# NUC200AN_v1 register map
File version: 1.0
Registers are 32-bit, read-write, reset 0x0 unless marked. A register's access mark holds for its fields unless they carry their own. Offsets are from the block's base; [hi:lo] are bit positions; {n}, {i} and the like mark numbered series; 'fields as' and 'values as' point back to an identical list.

## CLK — CLK Register Map
Base 0x50000200
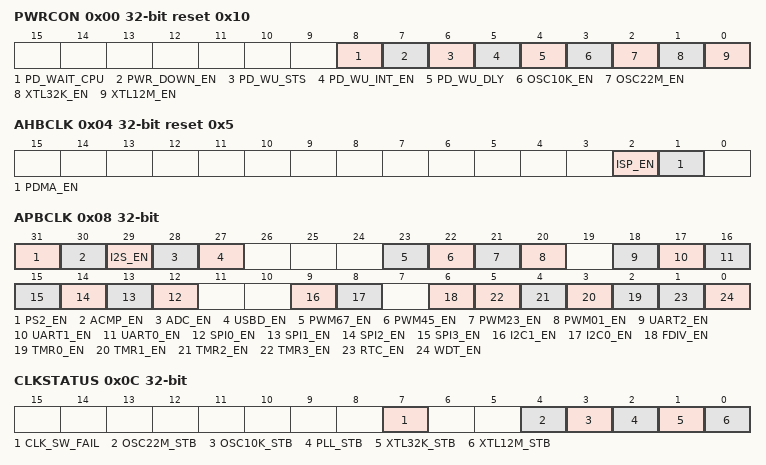
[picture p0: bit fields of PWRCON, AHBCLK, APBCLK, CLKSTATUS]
0x00 PWRCON reset 0x10 (reset mask 0xFFFFFFF0) — System Power-down Control Register
  [8] PD_WAIT_CPU — This Bit Control the Power-down Entry Condition (Write Protected)
    0=Chip enters Power-down mode when the PWR_DOWN_EN bit is set to 1; 1=Chip enters Power- down mode when the both PD_WAIT_CPU and PWR_DOWN_EN bits are set to 1 and CPU run WFI instruction
  [7] PWR_DOWN_EN — System Power-down Enable Bit (Write Protected). When this bit is set to 1, Power-down mode is enabled and chip power-down behavior will depend on the PD_WAIT_CPU bit (a) If the PD_WAIT_CPU is 0, then the chip enters Power-down mode immediately after the PWR_DOWN_EN bit set. (b) if the PD_WAIT_CPU is 1, then the chip keeps active till the CPU sleep mode is also active and then the chip enters Power-down mode. When chip wakes up from Power-down mode, this bit is cleared by hardware. User needs to set this bit again for next power-down. In Power-down mode, external 4~24 MHz high speed crystal oscillator and the internal 22.1184 MHz high speed oscillator will be disabled in this mode, but the external 32.768 kHz low speed crystal and internal 10 kHz low speed oscillator are not controlled by Power-down mode. In Power- down mode, the PLL and system clock are disabled, and ignored the clock source selection. The clocks of peripheral are not controlled by Power-down mode, if the peripheral clock source is from external 32.768 kHz low speed crystal oscillator or the internal 10 kHz low speed oscillator.
    0=Chip operating normally or chip in Idle mode because of WFI command; 1=Chip enters Power-down mode instantly or waits CPU sleep command WFI
  [6] PD_WU_STS — Power-down Mode Wake-up Interrupt Status. Set by "power-down wake-up event", it indicates that resume from Power-down mode" The flag is set if the GPIO, USB, UART, WDT, CAN, I2C, TIMER, ACMP, BOD or RTC wake-up occurred. Write 1 to clear the bit to 0. Note: This bit is working only if PD_WU_INT_EN (PWRCON[5]) set to 1.
  [5] PD_WU_INT_EN — Power-down Mode Wake-up Interrupt Enable (Write Protected). The interrupt will occur when both PD_WU_STS and PD_WU_INT_EN are high.
    0=Interrupt Disabled; 1=Interrupt Enabled
  [4] PD_WU_DLY — Enable the Wake-up Delay Counter (Write Protected). When the chip wakes up from Power-down mode, the clock control will delay certain clock cycles to wait system clock stable. The delayed clock cycle is 4096 clock cycles when chip work at external 4~24 MHz high speed crystal, and 256 clock cycles when chip work at internal 22.1184 MHz high speed oscillator.
    0=Clock cycles delay Disabled; 1=Clock cycles delay Enabled
  [3] OSC10K_EN — Internal 10 KHz Low Speed Oscillator Enable (Write Protected)
    0=Internal 10 kHz low speed oscillator Disabled; 1=Internal 10 kHz low speed oscillator Enabled
  [2] OSC22M_EN — Internal 22.1184 MHz High Speed Oscillator Enable (Write Protected)
    0=Internal 22.1184 MHz high speed oscillator Disabled; 1=Internal 22.1184 MHz high speed oscillator Enabled
  [1] XTL32K_EN — External 32.768 KHz Low Speed Crystal Enable (Write Protected)
    0=External 32.768 kHz low speed crystal oscillator Disabled; 1=External 32.768 kHz low speed crystal oscillator Enabled (Normal operation)
  [0] XTL12M_EN — External 4~24 MHz High Speed Crystal Enable (Write Protected). The bit default value is set by flash controller user configuration register config0 [26:24]. When the default clock source is from external 4~24 MHz high speed crystal, this bit is set to 1 automatically.
    0=External 4~24 MHz high speed crystal oscillator Disabled; 1=External 4~24 MHz high speed crystal oscillator Enabled
0x04 AHBCLK reset 0x5 — AHB Devices Clock Enable Control Register
  [2] ISP_EN — Flash ISP Controller Clock Enable Control
    0=Flash ISP peripheral clock Disabled; 1=Flash ISP peripheral clock Enabled
  [1] PDMA_EN — PDMA Controller Clock Enable Control
    0=PDMA peripheral clock Disabled; 1=PDMA peripheral clock Enabled
0x08 APBCLK (reset mask 0xFFFFFFF0) — APB Devices Clock Enable Control Register
  [31] PS2_EN — PS/2 Clock Enable
    0=PS/2 clock Disabled; 1=PS/2 clock Enabled
  [30] ACMP_EN — Analog Comparator Clock Enable
    0=Analog Comparator clock Disabled; 1=Analog Comparator clock Enabled
  [29] I2S_EN — I2S Clock Enable
    0=I2S clock Disabled; 1=I2S clock Enabled
  [28] ADC_EN — Analog-digital-converter (ADC) Clock Enable
    0=ADC clock Disabled; 1=ADC clock Enabled
  [27] USBD_EN — USB 2.0 FS Device Controller Clock Enable
    0=USB clock Enabled; 1=USB clock Enabled
  [23] PWM67_EN — PWM_67 Clock Enable
    0=PWM67 clock Disabled; 1=PWM67 clock Enabled
  [22] PWM45_EN — PWM_45 Clock Enable
    0=PWM45 clock Disabled; 1=PWM45 clock Enabled
  [21] PWM23_EN — PWM_23 Clock Enable
    0=PWM23 clock Disabled; 1=PWM23 clock Enabled
  [20] PWM01_EN — PWM_01 Clock Enable
    0=PWM01 clock Disabled; 1=PWM01 clock Enabled
  [18] UART2_EN — UART2 Clock Enable
    0=UART2 clock Disabled; 1=UART2 clock Enabled
  [17] UART1_EN — UART1 Clock Enable
    0=UART1 clock Disabled; 1=UART1 clock Enabled
  [16] UART0_EN — UART0 Clock Enable
    0=UART0 clock Disabled; 1=UART0 clock Enabled
  [n+12] SPI{n}_EN (n=0..3) — SPI{n} Clock Enable
    0=SPI{n} clock Disabled; 1=SPI{n} clock Enabled
  [9] I2C1_EN — I2C1 Clock Enable
    0=I2C1 clock Disabled; 1=I2C1 clock Enabled
  [8] I2C0_EN — I2C0 Clock Enable
    0=I2C0 clock Disabled; 1=I2C0 clock Enabled
  [6] FDIV_EN — Frequency Divider Output Clock Enable
    0=FDIV clock Disabled; 1=FDIV clock Enabled
  [n+2] TMR{n}_EN (n=0..3) — Timer{n} Clock Enable
    0=Timer{n} clock Disabled; 1=Timer{n} clock Enabled
  [1] RTC_EN — Real-time-clock APB Interface Clock Enable. This bit is used to control the RTC APB clock only, The RTC peripheral clock source is from the external 32.768 kHz low speed crystal.
    0=RTC clock Disabled; 1=RTC clock Enabled
  [0] WDT_EN — Watchdog Timer Clock Enable (Write Protected). This bit is the protected bit. It means programming this needs to write "59h", "16h", "88h" to address 0x5000_0100 to disable register protection. Refer to the register REGWRPROT at address GCR_BA+0x100.
    0=Watchdog Timer clock Disabled; 1=Watchdog Timer clock Enabled
0x0C CLKSTATUS (reset mask 0xFFFFFF00) — Clock Status Monitor Register
  [7] CLK_SW_FAIL — Clock Switching Fail Flag. This bit is updated when software switches system clock source. If switch target clock is stable, this bit will be set to 0. If switch target clock is not stable, this bit will be set to 1. Write 1 to clear the bit to 0.
    0=Clock switching success; 1=Clock switching failed
  [4] OSC22M_STB — Internal 22.1184 MHz High Speed Oscillator Clock Source Stable Flag. This bit is read only.
    0=Internal 22.1184 MHz high speed oscillator clock is not stable or disabled; 1=Internal 22.1184 MHz high speed oscillator clock is stable
  [3] OSC10K_STB — Internal 10 KHz Low Speed Oscillator Clock Source Stable Flag. This bit is read only.
    0=Internal 10 kHz low speed oscillator clock is not stable or disabled; 1=Internal 10 kHz low speed oscillator clock is stable
  [2] PLL_STB — Internal PLL Clock Source Stable Flag. This bit is read only.
    0=Internal PLL clock is not stable or disabled; 1=Internal PLL clock is stable
  [1] XTL32K_STB — External 32.768 KHz Low Speed Crystal Clock Source Stable Flag. This bit is read only.
    0=External 32.768 kHz low speed crystal clock is not stable or disabled; 1=External 32.768 kHz low speed crystal clock is stable
  [0] XTL12M_STB — External 4~24 MHz High Speed Crystal Clock Source Stable Flag. This bit is read only.
    0=External 4~24 MHz high speed crystal clock is not stable or disabled; 1=External 4~24 MHz high speed crystal clock is stable
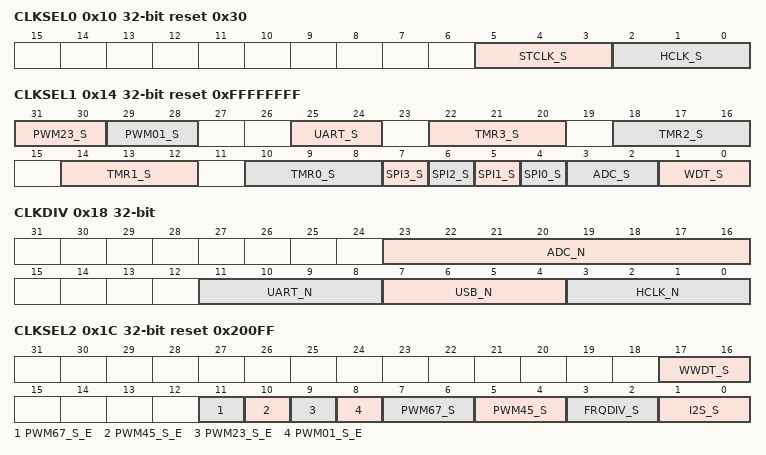
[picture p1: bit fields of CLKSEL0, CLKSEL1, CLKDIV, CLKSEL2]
0x10 CLKSEL0 reset 0x30 (reset mask 0xFFFFFFF0) — Clock Source Select Control Register 0
  [5:3] STCLK_S — Cortex-M0 SysTick Clock Source Select (Write-protection Bits)
    0=Clock source from external 4~24 MHz high speed crystal clock; 1=Clock source from external 32.768 kHz low speed crystal clock; 2=Clock source from external 4~24 MHz high speed crystal clock/2; 3=Clock source from HCLK/2; 7=Clock source from internal 22.1184 MHz high speed oscillator clock/2
  [2:0] HCLK_S — HCLK Clock Source Select (Write-protection Bits). Before clock switching, the related clock sources (both pre-select and new-select) must be turn on. The 3-bit default value is reloaded from the value of CFOSC (Config0[26:24]) in user configuration register of Flash controller by any reset. Therefore the default value is either 000b or 111b. These bits are protected bit. It means programming them needs to write "59h", "16h", and "88h" to address 0x5000_0100 to disable register protection. Refer to the register REGWRPROT at address GCR_BA+0x100.
    0=Clock source from external 4~24 MHz high speed crystal oscillator clock; 1=Clock source from external 32.768 kHz low speed crystal oscillator clock; 2=Clock source from PLL clock; 3=Clock source from internal 10 kHz low speed oscillator clock; 7=Clock source from internal 22.1184 MHz high speed oscillator clock
0x14 CLKSEL1 reset 0xFFFFFFFF — Clock Source Select Control Register 1
  [31:30] PWM23_S — PWM2 and PWM3 Clock Source Selection. PWM2 and PWM3 use the same Peripheral clock source; both of them use the same prescaler. The Peripheral clock source of PWM2 and PWM3 is defined by PWM23_S[2:0] and this field is combined by CLKSEL2[9] and CLKSEL1[31:30].
  [29:28] PWM01_S — PWM0 and PWM1 Clock Source Selection. PWM0 and PWM1 use the same Peripheral clock source, both of them use the same prescaler. The Peripheral clock source of PWM0 and PWM1 is defined by PWM01_S[2:0] and this field is combined by CLKSEL2[8] and CLKSEL1[29:28].
  [25:24] UART_S — UART Clock Source Selection
    0=Clock source from external 4~24 MHz high speed crystal oscillator clock; 1=Clock source from PLL clock; 3=Clock source from internal 22.1184 MHz high speed oscillator clock
  [4n+10:4n+8] TMR{n}_S (n=0..3) — TIMER{n} Clock Source Selection
    0=Clock source from external 4~24 MHz high speed crystal clock; 1=Clock source from external 32.768 kHz low speed crystal clock; 2=Clock source from HCLK; 3=Clock source from external trigger; 5=Clock source from internal 10 kHz low speed oscillator clock; 7=Clock source from internal 22.1184 MHz high speed oscillator clock
  [n+4] SPI{n}_S (n=0..3) — SPI{n} Clock Source Selection
    0=Clock source from PLL clock; 1=Clock source from HCLK
  [3:2] ADC_S — ADC Clock Source Select
    0=Clock source from external 4~24 MHz high speed crystal oscillator clock; 1=Clock source from PLL clock; 2=Clock source from HCLK; 3=Clock source from internal 22.1184 MHz high speed oscillator clock
  [1:0] WDT_S — Watchdog Timer Clock Source Select (Write-protection Bits). These bits are protected bits, and programming this needs to write "59h", "16h", and "88h" to address 0x5000_0100 to disable register protection. Refer to the register REGWRPROT at address GCR_BA+0x100.
    1=Clock source from external 32.768 kHz low speed crystal oscillator clock; 2=Clock source from HCLK/2048 clock; 3=Clock source from internal 10 kHz low speed oscillator clock
0x18 CLKDIV — Clock Divider Number Register
  [23:16] ADC_N — ADC Clock Divide Number From ADC Clock Source
  [11:8] UART_N — UART Clock Divide Number From UART Clock Source
  [7:4] USB_N — USB Clock Divide Number From PLL Clock
  [3:0] HCLK_N — HCLK Clock Divide Number From HCLK Clock Source
0x1C CLKSEL2 reset 0x200FF — Clock Source Select Control Register 2
  [17:16] WWDT_S — Window Watchdog Timer Clock Source Selection
    2=Clock source from HCLK/2048 clock; 3=Clock source from internal 10 kHz low speed oscillator clock
  [11] PWM67_S_E — PWM6 and PWM7 Clock Source Selection. PWM6 and PWM7 used the same Peripheral clock source; both of them used the same prescaler. The Peripheral clock source of PWM6 and PWM7 is defined by PWM67_S[2:0] and this field is combined by CLKSEL2[11] and CLKSEL2[7:6].
  [10] PWM45_S_E — PWM4 and PWM5 Clock Source Selection. PWM4 and PWM5 used the same Peripheral clock source; both of them used the same prescaler. The Peripheral clock source of PWM4 and PWM5 is defined by PWM45_S[2:0] and this field is combined by CLKSEL2[10] and CLKSEL2[5:4].
  [9] PWM23_S_E — PWM2 and PWM3 Clock Source Selection. PWM2 and PWM3 used the same Peripheral clock source; both of them used the same prescaler. The Peripheral clock source of PWM2 and PWM3 is defined by PWM23_S[2:0] and this field is combined by CLKSEL2[9] and CLKSEL1[31:30].
  [8] PWM01_S_E — PWM0 and PWM1 Clock Source Selection. PWM0 and PWM1 used the same Peripheral clock source; both of them used the same prescaler. The Peripheral clock source of PWM0 and PWM1 is defined by PWM01_S[2:0] and this field is combined by CLKSEL2[8] and CLKSEL1[29:28].
  [7:6] PWM67_S — PWM6 and PWM7 Clock Source Selection. PWM6 and PWM7 used the same Peripheral clock source; both of them used the same prescaler. The Peripheral clock source of PWM6 and PWM7 is defined by PWM67_S (CLKSEL2[7:6]) and PWM67_S_E (CLKSEL2[11]). this field is combined by CLKSEL2[11] and CLKSEL2[7:6].
  [5:4] PWM45_S — PWM4 and PWM5 Clock Source Selection. PWM4 and PWM5 used the same Peripheral clock source; both of them used the same prescaler. The Peripheral clock source of PWM4 and PWM5 is defined by PWM45_S[2:0] and this field is combined by CLKSEL2[10] and CLKSEL2[5:4].
  [3:2] FRQDIV_S — Clock Divider Clock Source Selection
    0=Clock source from external 4~24 MHz high speed crystal oscillator clock; 1=Clock source from external 32.768 kHz low speed crystal oscillator clock; 2=Clock source from HCLK; 3=Clock source from internal 22.1184 MHz high speed oscillator clock
  [1:0] I2S_S — I2S Clock Source Selection
    values as CLKSEL1.ADC_S
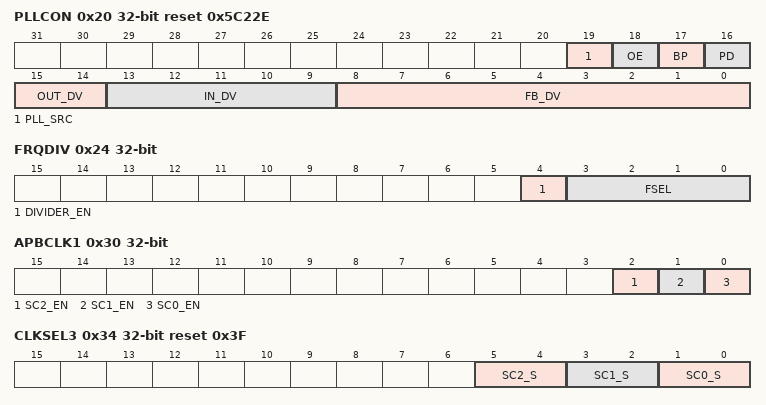
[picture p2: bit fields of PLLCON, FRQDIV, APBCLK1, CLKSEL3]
0x20 PLLCON reset 0x5C22E — PLL Control Register
  [19] PLL_SRC — PLL Source Clock Selection
    0=PLL source clock from external 4~24 MHz high speed crystal; 1=PLL source clock from internal 22.1184 MHz high speed oscillator
  [18] OE — PLL OE (FOUT Enable) Pin Control
    0=PLL FOUT Enabled; 1=PLL FOUT is fixed low
  [17] BP — PLL Bypass Control
    0=PLL is in Normal mode (default); 1=PLL clock output is same as PLL source clock input
  [16] PD — Power-down Mode. If the PWR_DOWN_EN bit is set to 1 in PWRCON register, the PLL will enter Power-down mode too.
    0=PLL is in Normal mode; 1=PLL is in Power-down mode (default)
  [15:14] OUT_DV — PLL Output Divider Control Bits. Refer to the formulas below the table.
  [13:9] IN_DV — PLL Input Divider Control Bits. Refer to the formulas below the table.
  [8:0] FB_DV — PLL Feedback Divider Control Bits. Refer to the formulas below the table.
0x24 FRQDIV — Frequency Divider Control Register
  [4] DIVIDER_EN — Frequency Divider Enable Bit
    0=Frequency Divider Disabled; 1=Frequency Divider Enabled
  [3:0] FSEL — Divider Output Frequency Selection Bits. The formula of output frequency is: Fin is the input clock frequency. Fout is the frequency of divider output clock. N is the 4-bit value of FSEL[3:0].
0x30 APBCLK1 — APB Devices Clock Enable Control Register 1
  [2] SC2_EN — SC2 Clock Enable
    0=SC2 clock Disabled; 1=SC2 clock Enabled
  [1] SC1_EN — SC1 Clock Enable
    0=SC1 clock Disabled; 1=SC1 clock Enabled
  [0] SC0_EN — SC0 Clock Enable
    0=SC0 Clock Disabled; 1=SC0 Clock Enabled
0x34 CLKSEL3 reset 0x3F — Clock Source Select Control Register 3
  [all] fields
    0=Clock source from external 4~24 MHz high speed crystal oscillator clock; 1=Clock source from PLL clock; 2=HCLK; 3=Clock source from internal 22.1184 MHz high speed oscillator clock
  [5:4] SC2_S — SC2 Clock Source Selection
  [3:2] SC1_S — SC1 Clock Source Selection
  [1:0] SC0_S — SC0 Clock Source Selection
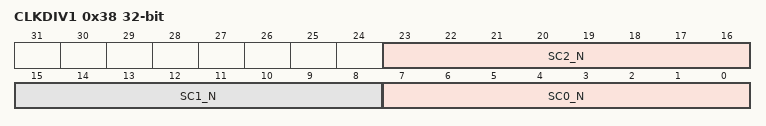
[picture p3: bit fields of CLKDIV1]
0x38 CLKDIV1 — Clock Divider Number Register 1
  [23:16] SC2_N — SC2 Clock Divide Number From SC2 Clock Source
  [15:8] SC1_N — SC1 Clock Divide Number From SC1 Clock Source
  [7:0] SC0_N — SC0 Clock Divide Number From SC0 Clock Source
